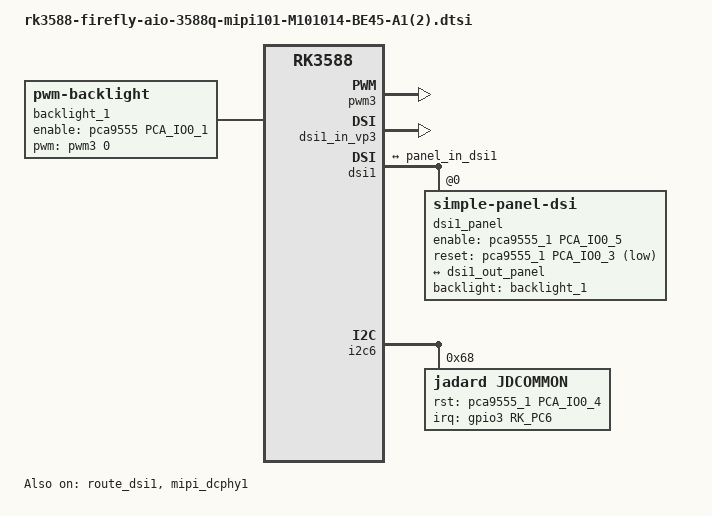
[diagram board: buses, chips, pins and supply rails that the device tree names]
// SPDX-License-Identifier: (GPL-2.0+ OR MIT)
/*
 * Copyright (c) 2021 Rockchip Electronics Co., Ltd.
 *
 */
 #define WHICHDSI 1 /* dsi0 = 0,dsi1 = 1*/
 / {
#if WHICHDSI	 
/*
   vcc1v8_lcd1_power: vcc1v8-lcd1-power-regulator {
		compatible = "regulator-fixed";
		enable-active-high;
		gpio = <&pca9555 PCA_IO0_1 GPIO_ACTIVE_HIGH>;
		regulator-always-on;
	};
*/
	backlight_1: backlight {
		status = "okay";
		compatible = "pwm-backlight";
		enable-gpios = <&pca9555 PCA_IO0_1 GPIO_ACTIVE_HIGH>;
		pwms = <&pwm3 0 50000 1>;
		brightness-levels = <
			 60  60  60  61  61  61  62  62
			 62  63  63  63  64  64  64  65
			 65  65  66  66  66  67  67  67
			 68  68  68  69  69  69  70  70
			 70  71  71  71  72  72  72  73
			 73  73  74  74  74  75  75  75
			 76  76  76  77  77  77  78  78
			 78  79  79  79  80  80  80  81
			 81  81  82  82  82  83  83  83
			 84  84  84  85  85  85  86  86
			 86  87  87  87  88  88  88  89
			 89  89  90  91  92  93  94  95
			 96  97  98  99 100 101 102 103
			104 105 106 107 108 109 110 111
			112 113 114 115 116 117 118 119
			120 121 122 123 124 125 126 127
			128 129 130 131 132 133 134 135
			136 137 138 139 140 141 142 143
			144 145 146 147 148 149 150 151
			152 153 154 155 156 157 158 159
			160 161 162 163 164 165 166 167
			168 169 170 171 172 173 174 175
			176 177 178 179 180 181 182 183
			184 185 186 187 188 189 190 191
			192 193 194 195 196 197 198 199
			200 201 202 203 204 205 206 207
			208 209 210 211 212 213 214 215
			216 217 218 219 220 221 222 223
			224 225 226 227 228 229 230 231
			232 233 234 235 236 237 238 239
			240 241 242 243 244 245 246 247
			248 249 250 251 252 253 254 255
		>;
		default-brightness-level = <150>;
	};	

#else
/*
	vcc1v8_lcd0_power: vcc1v8-lcd0-power-regulator {
		compatible = "regulator-fixed";
		enable-active-high;
		gpio = <&pca9555 PCA_IO0_2 GPIO_ACTIVE_HIGH>;
		regulator-always-on;
	};
*/
	backlight: backlight {
		status = "okay";
		compatible = "pwm-backlight";
		//enable-gpios = <&gpio2 RK_PB5 GPIO_ACTIVE_HIGH>;
		enable-gpios = <&gpio2 RK_PB5 GPIO_ACTIVE_LOW>;
		pwms = <&pwm12 0 50000 0>;
		brightness-levels = <
			 60  60  60  61  61  61  62  62
			 62  63  63  63  64  64  64  65
			 65  65  66  66  66  67  67  67
			 68  68  68  69  69  69  70  70
			 70  71  71  71  72  72  72  73
			 73  73  74  74  74  75  75  75
			 76  76  76  77  77  77  78  78
			 78  79  79  79  80  80  80  81
			 81  81  82  82  82  83  83  83
			 84  84  84  85  85  85  86  86
			 86  87  87  87  88  88  88  89
			 89  89  90  91  92  93  94  95
			 96  97  98  99 100 101 102 103
			104 105 106 107 108 109 110 111
			112 113 114 115 116 117 118 119
			120 121 122 123 124 125 126 127
			128 129 130 131 132 133 134 135
			136 137 138 139 140 141 142 143
			144 145 146 147 148 149 150 151
			152 153 154 155 156 157 158 159
			160 161 162 163 164 165 166 167
			168 169 170 171 172 173 174 175
			176 177 178 179 180 181 182 183
			184 185 186 187 188 189 190 191
			192 193 194 195 196 197 198 199
			200 201 202 203 204 205 206 207
			208 209 210 211 212 213 214 215
			216 217 218 219 220 221 222 223
			224 225 226 227 228 229 230 231
			232 233 234 235 236 237 238 239
			240 241 242 243 244 245 246 247
			248 249 250 251 252 253 254 255
		>;
		default-brightness-level = <250>;
	};	
 
#endif
 };
 #if WHICHDSI 

&pwm3 {
	pinctrl-0 = <&pwm3m3_pins>;
	status = "okay";
};

&route_dsi1 {
	status = "okay";
	connect = <&vp3_out_dsi1>;
};

&dsi1_in_vp3 {
	status = "okay";
};

&mipi_dcphy1 {
	status = "okay";
};

&dsi1 {
	status = "okay";
	//rockchip,lane-rate = <1000>;
	dsi1_panel: panel@0 {
		status = "okay";
		compatible = "simple-panel-dsi";
		reg = <0>;
		backlight = <&backlight_1>;
		
		enable-gpios = <&pca9555_1 PCA_IO0_5 GPIO_ACTIVE_HIGH>;
		reset-gpios = <&pca9555_1 PCA_IO0_3 GPIO_ACTIVE_LOW>;
		enable-delay-ms = <50>;
		prepare-delay-ms = <200>;
		reset-delay-ms = <50>;
		init-delay-ms = <55>;
		unprepare-delay-ms = <50>;
		disable-delay-ms = <20>;
		mipi-data-delay-ms = <200>;
		//size,width = <120>;
		//size,height = <170>;
		size,width = <136>;
		size,height = <217>;
		dsi,flags = <(MIPI_DSI_MODE_VIDEO | MIPI_DSI_MODE_VIDEO_BURST | MIPI_DSI_MODE_LPM | MIPI_DSI_MODE_EOT_PACKET)>;
		dsi,format = <MIPI_DSI_FMT_RGB888>;
		dsi,lanes  = <4>;

	/*	panel-init-sequence = [
			//39 00 04 B9 83 10 2E
			// 15 00 02 CF FF
			99 00 02 04 83
			05 78 01 11
			05 32 01 29
			//15 00 02 35 00
		];
*/
		panel-init-sequence = [			
		15 00 02 30 01		
		39 00 05 78 49 61 02 00		
		15 00 02 30 02		
		15 00 02 31 22		
		15 00 02 32 0C		
		15 00 02 33 30		
		15 00 02 3d 42		
		15 00 02 3f 61		
		15 00 02 42 82		
		15 00 02 44 21		
		15 00 02 49 C2		
		15 00 02 4A 3F
		39 00 0D 41 0C 0C 1C 1C 0C 0C 1C 1C 0C 0C 00 00
		39 00 0C 5a 23 23 1C 18 20 21 12 10 0E 0C 0A	
		39 00 0C 5b 08 00 23 23 23 23 23 23 23 23 23
		39 00 0C 5c 23 23 1D 19 20 21 13 11 0F 0D 0B
		39 00 0C 5d 09 01 23 23 23 23 23 23 23 23 23	
		39 00 0C 5e 23 23 1D 01 20 21 11 13 09 0B 0D		
		39 00 0C 5f 0F 19 23 23 23 23 23 23 23 23 23		
		39 00 0C 60 23 23 1C 00 20 21 10 12 08 0A 0C		
		39 00 0C 61 0E 18 23 23 23 23 23 23 23 23 23
		15 00 02 68 80		
		39 00 03 4E 05 05	
		39 00 03 50 01 01		
		39 00 03 55 FA FA		
		39 00 03 56 FA FA	
		39 00 04 6F 20 00 00
		39 00 04 70 20 00 00	
		39 00 04 71 FF FF 3F
		39 00 04 72 FF FF 3F
		15 00 02 30 05		
		15 00 02 31 00	
		39 00 04 40 6F 39 39		
		15 00 02 30 07		
		15 00 02 31 c0	
		15 00 02 30 08	
		15 00 02 31 04
		15 00 02 33 05		
		15 00 02 47 0A	
		15 00 02 48 0C	
		15 00 02 50 0D
		15 00 02 5A 20		
		15 00 02 5B 00		
		15 00 02 5C 53
		15 00 02 62 04	
		15 00 02 65 5F		
		15 00 02 5e 00		
		15 00 02 73 01	
		15 00 02 30 0a	
		15 00 02 33 00	
		15 00 02 3f 50
		15 00 02 42 31
		15 00 02 43 00	
		15 00 02 49 03		
		15 00 02 30 0b
		39 00 03 33 00 63	
		39 00 03 3c 00 68	
		15 00 02 43 B0	
		15 00 02 44 30	
		39 00 06 3e 00 01 05 09 0C
		39 00 0F 3f 09 1B 1F 24 20 3B 43 4D 61 64 72 7F 95 97	
		39 00 0A 40 4B 53 5C 65 00 01 05 09 0C	
		39 00 0F 41 09 1B 1F 24 20 3B 43 4D 61 64 72 7F 95 97		
		39 00 05 42 4B 53 5C 65		
		15 00 02 45 43
		15 00 02 46 5A
		15 00 02 48 28
		15 00 02 49 29		
		15 00 02 4A 1B		
		15 00 02 4E 0A		
		15 00 02 4F 96		
		15 00 02 50 50
		15 00 02 5A 04	
		15 00 02 5B 43
		15 00 02 60 07
		15 00 02 61 28		
		15 00 02 67 13		
		15 00 02 30 0C		
		15 00 02 4A AB		
		15 00 02 4B D3
		15 00 02 32 62		
		15 00 02 42 34
		15 00 02 5e 00
		15 00 02 6a 7f		
		15 00 02 62 41	
		15 00 02 30 0d
		15 00 02 4c 74	
		15 00 02 30 08	
		15 00 02 52 C3	
		15 00 02 54 20	
		15 00 02 30 08		
		15 00 02 30 00		
		15 78 02 11 00			
		15 32 02 29 00		
		15 00 02 35 00	
		15 00 02 30 0C		
		15 00 02 4A AB		
		15 00 02 4B D3		
		15 00 02 30 00
		05 78 01 29
		05 00 01 11				
		];

		panel-exit-sequence = [
			//05 00 01 28
			//05 00 01 10
			05 14 01 28
			05 50 01 10
		];

		dis1_timings0: display-timings {
			native-mode = <&dsi1_timing0>;
			dsi1_timing0: timing0 {
	/*			clock-frequency = <72600000>;//<80000000>;
				hactive = <800>;//<768>;
				vactive = <1280>;
				hsync-len = <14>;   //20, 50,10
				hback-porch = <26>; //50, 56,10
				hfront-porch = <32>;//50, 30,180
				vsync-len = <8>;//4
				vback-porch = <20>;//4
				vfront-porch = <80>;//8
				hsync-active = <0>;
				vsync-active = <0>;
				de-active = <0>;
				pixelclk-active = <0>;
*/

				//clock-frequency = <72600000>;//<80000000>;
                 clock-frequency = <79100000>;//<80000000>;
				//clock-frequency = <23700000>;//<80000000>;1/4 clock
				hactive = <800>;//<768>;
				vactive = <1280>;

				hsync-len = <8>;   //20, 50,10
				hback-porch = <28>; //50, 56,10
				hfront-porch = <40>;//50, 30,180

				vsync-len = <8>;//4
				vback-porch = <38>;//4
				vfront-porch = <180>;//8


				hsync-active = <0>;
				vsync-active = <0>;
				de-active = <0>;
				pixelclk-active = <0>;

			};
		};

		ports {
			#address-cells = <1>;
			#size-cells = <0>;

			port@0 {
				reg = <0>;
				panel_in_dsi1: endpoint {
					remote-endpoint = <&dsi1_out_panel>;
				};
			};
		};
	};

	ports {
		#address-cells = <1>;
		#size-cells = <0>;

		port@1 {
			reg = <1>;
			dsi1_out_panel: endpoint {
			remote-endpoint = <&panel_in_dsi1>;
			};
		};
	};
};

&i2c6{
	status = "okay";
	pinctrl-names = "default";
	pinctrl-0 = <&i2c6m0_xfer>;

	/*hxchipset@48{
		status = "okay";
		compatible = "himax,hxcommon";
		reg = <0x48>;

		himax,rst-gpio =  <&pca9555_1 PCA_IO0_4 GPIO_ACTIVE_HIGH>;
		himax,irq-gpio = <&gpio3 RK_PC6 IRQ_TYPE_LEVEL_HIGH>;
        pinctrl-names = "default";
        pinctrl-0 = <&touch_int1>;
		//himax,3v3-gpio = <&gpio0 RK_PB4 GPIO_ACTIVE_HIGH>;
		//himax,pon-gpio = <&gpio0 RK_PB4 GPIO_ACTIVE_HIGH>;

		//pinctrl-names = "default";
		//pinctrl-0 = <&lcd_tp_int>;

		himax,panel-coords = <0 800 0 1280>;      //触摸范围
		himax,display-coords = <0 800 0 1280>;    //分辨率
		report_type = <1>;
	};
*/

       jadard@68 {
        status = "okay";
        compatible = "jadard,jdcommon";
        reg = <0x68>;
	    jadard,rst-gpio = <&pca9555_1 PCA_IO0_4 GPIO_ACTIVE_HIGH>;
        jadard,irq-gpio = <&gpio3 RK_PC6 IRQ_TYPE_LEVEL_HIGH>;
       

        jadard,panel-max-points = <10>;
        jadard,int-is-edge =<1>;
        jadard,panel-sense-nums = <22 36>;
        jadard,panel-coords = <0 800 0 1280>;
    };

};


#else

&dsi0_in_vp3 {
	status = "okay";
};

&pwm12 {
	pinctrl-0 = <&pwm12m1_pins>;
	status = "okay";
};

&route_dsi0 {
	status = "okay";
	connect = <&vp3_out_dsi0>;
};

&mipi_dcphy0 {
	status = "okay";
};

&dsi0 {
	status = "okay";
	//rockchip,lane-rate = <1000>;
	dsi0_panel: panel@0 {
		status = "okay";
		compatible = "simple-panel-dsi";
		reg = <0>;
		backlight = <&backlight>;
		
		enable-gpios = <&pca9555 PCA_IO0_2 GPIO_ACTIVE_HIGH>;
		reset-gpios = <&gpio2 RK_PB4 GPIO_ACTIVE_LOW>;

		enable-delay-ms = <50>;
		prepare-delay-ms = <200>;
		reset-delay-ms = <50>;
		init-delay-ms = <55>;
		unprepare-delay-ms = <50>;
		disable-delay-ms = <20>;
		mipi-data-delay-ms = <200>;


/*		enable-delay-ms = <20>;
		prepare-delay-ms = <20>;
		reset-delay-ms = <20>;
		init-delay-ms = <20>;
		unprepare-delay-ms = <20>;
		disable-delay-ms = <20>;
		mipi-data-delay-ms = <20>;
*/
		//size,width = <120>;
		//size,height = <170>;
		size,width = <136>;
		size,height = <217>;
		dsi,flags = <(MIPI_DSI_MODE_VIDEO | MIPI_DSI_MODE_VIDEO_BURST | MIPI_DSI_MODE_LPM | MIPI_DSI_MODE_EOT_PACKET | MIPI_DSI_CLOCK_NON_CONTINUOUS)>;
		dsi,format = <MIPI_DSI_FMT_RGB888>;
		dsi,lanes  = <4>;

		/*panel-init-sequence = [
			//39 00 04 B9 83 10 2E
			// 15 00 02 CF FF
			99 00 02 04 83
			05 78 01 11
			05 32 01 29
			//15 00 02 35 00
		];

		panel-exit-sequence = [
			05 00 01 28
			05 00 01 10
		];*/

		panel-init-sequence = [			
		15 00 02 30 01		
		39 00 05 78 49 61 02 00		
		15 00 02 30 02		
		15 00 02 31 22		
		15 00 02 32 0C		
		15 00 02 33 30		
		15 00 02 3d 42		
		15 00 02 3f 61		
		15 00 02 42 82		
		15 00 02 44 21		
		15 00 02 49 C2		
		15 00 02 4A 3F
		39 00 0D 41 0C 0C 1C 1C 0C 0C 1C 1C 0C 0C 00 00
		39 00 0C 5a 23 23 1C 18 20 21 12 10 0E 0C 0A	
		39 00 0C 5b 08 00 23 23 23 23 23 23 23 23 23
		39 00 0C 5c 23 23 1D 19 20 21 13 11 0F 0D 0B
		39 00 0C 5d 09 01 23 23 23 23 23 23 23 23 23	
		39 00 0C 5e 23 23 1D 01 20 21 11 13 09 0B 0D		
		39 00 0C 5f 0F 19 23 23 23 23 23 23 23 23 23		
		39 00 0C 60 23 23 1C 00 20 21 10 12 08 0A 0C		
		39 00 0C 61 0E 18 23 23 23 23 23 23 23 23 23
		15 00 02 68 80		
		39 00 03 4E 05 05	
		39 00 03 50 01 01		
		39 00 03 55 FA FA		
		39 00 03 56 FA FA	
		39 00 04 6F 20 00 00
		39 00 04 70 20 00 00	
		39 00 04 71 FF FF 3F
		39 00 04 72 FF FF 3F
		15 00 02 30 05		
		15 00 02 31 00	
		39 00 04 40 6F 39 39		
		15 00 02 30 07		
		15 00 02 31 c0	
		15 00 02 30 08	
		15 00 02 31 04
		15 00 02 33 05		
		15 00 02 47 0A	
		15 00 02 48 0C	
		15 00 02 50 0D
		15 00 02 5A 20		
		15 00 02 5B 00		
		15 00 02 5C 53
		15 00 02 62 04	
		15 00 02 65 5F		
		15 00 02 5e 00		
		15 00 02 73 01	
		15 00 02 30 0a	
		15 00 02 33 00	
		15 00 02 3f 50
		15 00 02 42 31
		15 00 02 43 00	
		15 00 02 49 03		
		15 00 02 30 0b
		39 00 03 33 00 63	
		39 00 03 3c 00 68	
		15 00 02 43 B0	
		15 00 02 44 30	
		39 00 06 3e 00 01 05 09 0C
		39 00 0F 3f 09 1B 1F 24 20 3B 43 4D 61 64 72 7F 95 97	
		39 00 0A 40 4B 53 5C 65 00 01 05 09 0C	
		39 00 0F 41 09 1B 1F 24 20 3B 43 4D 61 64 72 7F 95 97		
		39 00 05 42 4B 53 5C 65		
		15 00 02 45 43
		15 00 02 46 5A
		15 00 02 48 28
		15 00 02 49 29		
		15 00 02 4A 1B		
		15 00 02 4E 0A		
		15 00 02 4F 96		
		15 00 02 50 50
		15 00 02 5A 04	
		15 00 02 5B 43
		15 00 02 60 07
		15 00 02 61 28		
		15 00 02 67 13		
		15 00 02 30 0C		
		15 00 02 4A AB		
		15 00 02 4B D3
		15 00 02 32 62		
		15 00 02 42 34
		15 00 02 5e 00
		15 00 02 6a 7f		
		15 00 02 62 41	
		15 00 02 30 0d
		15 00 02 4c 74	
		15 00 02 30 08	
		15 00 02 52 C3	
		15 00 02 54 20	
		15 00 02 30 08		
		15 00 02 30 00		
		15 78 02 11 00			
		15 32 02 29 00		
		15 00 02 35 00	
		15 00 02 30 0C		
		15 00 02 4A AB		
		15 00 02 4B D3		
		15 00 02 30 00
		05 78 01 29
		05 00 01 11				
		];

		panel-exit-sequence = [
			05 14 01 28
			05 50 01 10
			//05 00 01 28
			//05 00 01 10
		];

		/*disp_timings0: display-timings {
			native-mode = <&dsi0_timing0>;
			dsi0_timing0: timing0 {
				clock-frequency = <72600000>;//<80000000>;
				hactive = <800>;//<768>;
				vactive = <1280>;
				hsync-len = <14>;   //20, 50,10
				hback-porch = <26>; //50, 56,10
				hfront-porch = <32>;//50, 30,180
				vsync-len = <8>;//4
				vback-porch = <20>;//4
				vfront-porch = <80>;//8
				hsync-active = <0>;
				vsync-active = <0>;
				de-active = <0>;
				pixelclk-active = <0>;
			};
		};*/

		disp_timings0: display-timings {
			native-mode = <&dsi0_timing0>;
			dsi0_timing0: timing0 {
				//clock-frequency = <72600000>;//<80000000>;
                                clock-frequency = <79100000>;//<80000000>;
				//clock-frequency = <23700000>;//<80000000>;1/4 clock
				hactive = <800>;//<768>;
				vactive = <1280>;

				hsync-len = <8>;   //20, 50,10
				hback-porch = <28>; //50, 56,10
				hfront-porch = <40>;//50, 30,180

				vsync-len = <8>;//4
				vback-porch = <38>;//4
				vfront-porch = <180>;//8


				hsync-active = <0>;
				vsync-active = <0>;
				de-active = <0>;
				pixelclk-active = <0>;
			};
		};

		ports {
			#address-cells = <1>;
			#size-cells = <0>;

			port@0 {
				reg = <0>;
				panel_in_dsi: endpoint {
					remote-endpoint = <&dsi_out_panel>;
				};
			};
		};
	};

	ports {
		#address-cells = <1>;
		#size-cells = <0>;

		port@1 {
			reg = <1>;
			dsi_out_panel: endpoint {
			remote-endpoint = <&panel_in_dsi>;
			};
		};
	};
};


&i2c1{
	status = "okay";
	
	pinctrl-names = "default";
	pinctrl-0 = <&i2c1m2_xfer>;

	/*hxchipset@48{
		status = "okay";
                //status = "disabled";
		compatible = "himax,hxcommon";
		reg = <0x48>;
		//reg = <0x90>;

		himax,rst-gpio =  <&gpio3 RK_PC1 GPIO_ACTIVE_HIGH>;
		himax,irq-gpio = <&gpio3 RK_PC0 IRQ_TYPE_LEVEL_HIGH>;
		//himax,3v3-gpio = <&gpio0 RK_PB4 GPIO_ACTIVE_HIGH>;
		//himax,pon-gpio = <&gpio0 RK_PB4 GPIO_ACTIVE_HIGH>;
		pinctrl-names = "default";
        	pinctrl-0 = <&touch_int0>;
		//pinctrl-names = "default";
		//pinctrl-0 = <&lcd_tp_int>;

		himax,panel-coords = <0 800 0 1280>;      //触摸范围
		himax,display-coords = <0 800 0 1280>;    //分辨率
		report_type = <1>;
	};*/

       jadard@68 {
        status = "okay";
        compatible = "jadard,jdcommon";
        reg = <0x68>;
        jadard,irq-gpio = <&gpio3 RK_PC0 IRQ_TYPE_LEVEL_HIGH>;
        jadard,rst-gpio = <&gpio3 RK_PC1 GPIO_ACTIVE_HIGH>;

        jadard,panel-max-points = <10>;
        jadard,int-is-edge =<1>;
        jadard,panel-sense-nums = <22 36>;
        jadard,panel-coords = <0 800 0 1280>;
    };
};

/*
jadard@68 {
        status = "okay";
        compatible = "jadard,jdcommon";
        reg = <0x68>;
        jadard,irq-gpio = <&gpio3 RK_PC0 IRQ_TYPE_LEVEL_HIGH>;
        jadard,rst-gpio = <&gpio3 RK_PC1 GPIO_ACTIVE_HIGH>;

        jadard,panel-max-points = <10>;
        jadard,int-is-edge =<1>;
        jadard,panel-sense-nums = <22 36>;
        jadard,panel-coords = <0 800 0 1280>;
    };

*/
#endif


&pinctrl {
	touch {
		
		touch_int1: touch-int1 {
			rockchip,pins = <3 RK_PC6 RK_FUNC_GPIO &pcfg_pull_up>;
		};
		touch_int0: touch-int0 {
			rockchip,pins = <3 RK_PC0 RK_FUNC_GPIO &pcfg_pull_up>;
		};
	};
};
